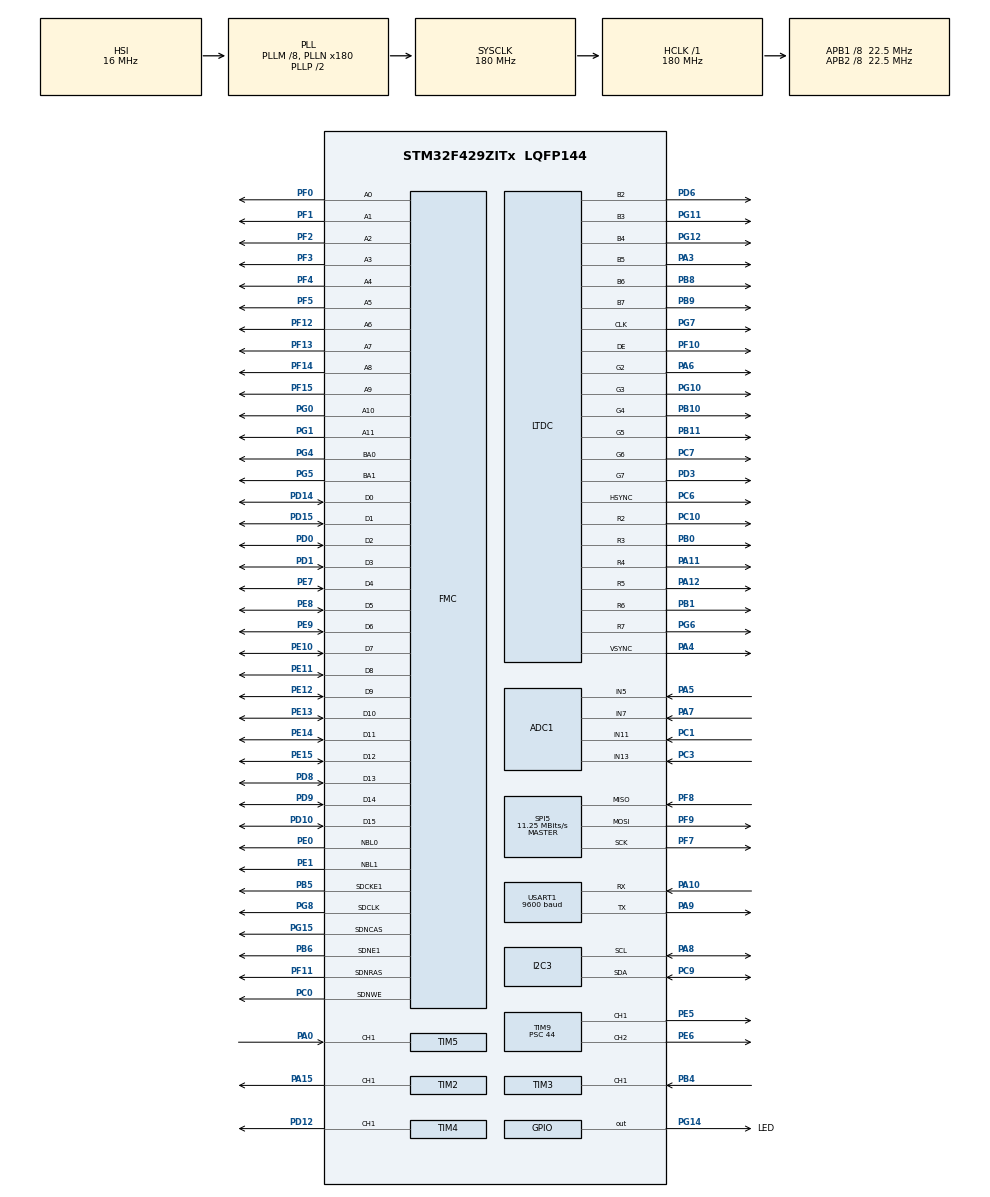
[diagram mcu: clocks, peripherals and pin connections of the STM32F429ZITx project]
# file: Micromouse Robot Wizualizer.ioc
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ADC1.Channel-1\#ChannelRegularConversion=ADC_CHANNEL_11
ADC1.NbrOfConversionFlag=1
ADC1.Rank-1\#ChannelRegularConversion=1
ADC1.SamplingTime-1\#ChannelRegularConversion=ADC_SAMPLETIME_3CYCLES
ADC1.master=1
DMA2D.ColorMode=DMA2D_OUTPUT_RGB565
LTDC.ActiveH=240
LTDC.ActiveW=320
Mcu.Family=STM32F4
Mcu.Name=STM32F429ZITx
Mcu.Package=LQFP144
NVIC.PriorityGroup=NVIC_PRIORITYGROUP_0
NVIC.USART1_IRQn=true\:0\:0\:false\:false\:true\:true\:true
PA0/WKUP.Signal=S_TIM5_CH1
PA10.Mode=Asynchronous
PA10.Signal=USART1_RX
PA11.Mode=RGB666
PA11.Signal=LTDC_R4
PA12.Mode=RGB666
PA12.Signal=LTDC_R5
PA15.Signal=S_TIM2_CH1_ETR
PA3.Mode=RGB666
PA3.Signal=LTDC_B5
PA4.Mode=RGB666
PA4.Signal=LTDC_VSYNC
PA5.Signal=ADCx_IN5
PA6.Mode=RGB666
PA6.Signal=LTDC_G2
PA7.Signal=ADCx_IN7
PA8.Mode=I2C
PA8.Signal=I2C3_SCL
PA9.Mode=Asynchronous
PA9.Signal=USART1_TX
PB0.Mode=RGB666
PB0.Signal=LTDC_R3
PB1.Mode=RGB666
PB1.Signal=LTDC_R6
PB10.Mode=RGB666
PB10.Signal=LTDC_G4
PB11.Mode=RGB666
PB11.Signal=LTDC_G5
PB4.GPIO_Speed=GPIO_SPEED_FREQ_HIGH
PB4.Signal=S_TIM3_CH1
PB5.Mode=SdramChipSelect2_1
PB5.Signal=FMC_SDCKE1
PB6.Mode=SdramChipSelect2_1
PB6.Signal=FMC_SDNE1
PB8.Mode=RGB666
PB8.Signal=LTDC_B6
PB9.Mode=RGB666
PB9.Signal=LTDC_B7
PC0.Signal=FMC_SDNWE
PC1.Signal=ADCx_IN11
PC10.Mode=RGB666
PC10.Signal=LTDC_R2
PC3.Signal=ADCx_IN13
PC6.Mode=RGB666
PC6.Signal=LTDC_HSYNC
PC7.Mode=RGB666
PC7.Signal=LTDC_G6
PC9.Mode=I2C
PC9.Signal=I2C3_SDA
PD0.Signal=FMC_D2_DA2
PD1.Signal=FMC_D3_DA3
PD10.Signal=FMC_D15_DA15
PD12.GPIO_PuPd=GPIO_NOPULL
PD12.Signal=S_TIM4_CH1
PD14.Signal=FMC_D0_DA0
PD15.Signal=FMC_D1_DA1
PD3.Mode=RGB666
PD3.Signal=LTDC_G7
PD6.Mode=RGB666
PD6.Signal=LTDC_B2
PD8.Signal=FMC_D13_DA13
PD9.Signal=FMC_D14_DA14
PE0.Signal=FMC_NBL0
PE1.Signal=FMC_NBL1
PE10.Signal=FMC_D7_DA7
PE11.Signal=FMC_D8_DA8
PE12.Signal=FMC_D9_DA9
PE13.Signal=FMC_D10_DA10
PE14.Signal=FMC_D11_DA11
PE15.Signal=FMC_D12_DA12
PE5.Signal=S_TIM9_CH1
PE6.Signal=S_TIM9_CH2
PE7.Signal=FMC_D4_DA4
PE8.Signal=FMC_D5_DA5
PE9.Signal=FMC_D6_DA6
PF0.Signal=FMC_A0
PF1.Signal=FMC_A1
PF10.Mode=RGB666
PF10.Signal=LTDC_DE
PF11.Signal=FMC_SDNRAS
PF12.Signal=FMC_A6
PF13.Signal=FMC_A7
PF14.Signal=FMC_A8
PF15.Signal=FMC_A9
PF2.Signal=FMC_A2
PF3.Signal=FMC_A3
PF4.Signal=FMC_A4
PF5.Signal=FMC_A5
PF7.Mode=Full_Duplex_Master
PF7.Signal=SPI5_SCK
PF8.Mode=Full_Duplex_Master
PF8.Signal=SPI5_MISO
PF9.Mode=Full_Duplex_Master
PF9.Signal=SPI5_MOSI
PG0.Signal=FMC_A10
PG1.Signal=FMC_A11
PG10.Mode=RGB666
PG10.Signal=LTDC_G3
PG11.Mode=RGB666
PG11.Signal=LTDC_B3
PG12.Mode=RGB666
PG12.Signal=LTDC_B4
PG14.GPIO_Label=LED
PG14.Signal=GPIO_Output
PG15.Signal=FMC_SDNCAS
PG4.Signal=FMC_A14_BA0
PG5.Signal=FMC_A15_BA1
PG6.Mode=RGB666
PG6.Signal=LTDC_R7
PG7.Mode=RGB666
PG7.Signal=LTDC_CLK
PG8.Signal=FMC_SDCLK
ProjectManager.HeapSize=0x200
ProjectManager.StackSize=0x400
ProjectManager.TargetToolchain=STM32CubeIDE
RCC.48MHZClocksFreq_Value=51428571.428571425
RCC.AHBFreq_Value=180000000
RCC.APB1CLKDivider=RCC_HCLK_DIV8
RCC.APB1Freq_Value=22500000
RCC.APB1TimFreq_Value=45000000
RCC.APB2CLKDivider=RCC_HCLK_DIV8
RCC.APB2Freq_Value=22500000
RCC.APB2TimFreq_Value=45000000
RCC.CortexFreq_Value=180000000
RCC.HCLKFreq_Value=180000000
RCC.HSE_VALUE=8000000
RCC.HSI_VALUE=16000000
RCC.LSE_VALUE=32768
RCC.PLLM=8
RCC.PLLN=180
RCC.PLLQ=7
RCC.PLLSAIN=216
RCC.SYSCLKFreq_VALUE=180000000
RCC.SYSCLKSource=RCC_SYSCLKSOURCE_PLLCLK
RCC.VCOOutputFreq_Value=360000000
SH.ADCx_IN11.0=ADC1_IN11,IN11
SH.ADCx_IN13.0=ADC1_IN13,IN13
SH.ADCx_IN5.0=ADC1_IN5,IN5
SH.ADCx_IN7.0=ADC1_IN7,IN7
SH.FMC_A0.0=FMC_A0,12b-sda1
SH.FMC_A1.0=FMC_A1,12b-sda1
SH.FMC_A10.0=FMC_A10,12b-sda1
SH.FMC_A11.0=FMC_A11,12b-sda1
SH.FMC_A14_BA0.0=FMC_BA0,FourSdramBanks1
SH.FMC_A15_BA1.0=FMC_BA1,FourSdramBanks1
SH.FMC_A2.0=FMC_A2,12b-sda1
SH.FMC_A3.0=FMC_A3,12b-sda1
SH.FMC_A4.0=FMC_A4,12b-sda1
SH.FMC_A5.0=FMC_A5,12b-sda1
SH.FMC_A6.0=FMC_A6,12b-sda1
SH.FMC_A7.0=FMC_A7,12b-sda1
SH.FMC_A8.0=FMC_A8,12b-sda1
SH.FMC_A9.0=FMC_A9,12b-sda1
SH.FMC_D0_DA0.0=FMC_D0,sd-16b-d1
SH.FMC_D10_DA10.0=FMC_D10,sd-16b-d1
SH.FMC_D11_DA11.0=FMC_D11,sd-16b-d1
SH.FMC_D12_DA12.0=FMC_D12,sd-16b-d1
SH.FMC_D13_DA13.0=FMC_D13,sd-16b-d1
SH.FMC_D14_DA14.0=FMC_D14,sd-16b-d1
SH.FMC_D15_DA15.0=FMC_D15,sd-16b-d1
SH.FMC_D1_DA1.0=FMC_D1,sd-16b-d1
SH.FMC_D2_DA2.0=FMC_D2,sd-16b-d1
SH.FMC_D3_DA3.0=FMC_D3,sd-16b-d1
SH.FMC_D4_DA4.0=FMC_D4,sd-16b-d1
SH.FMC_D5_DA5.0=FMC_D5,sd-16b-d1
SH.FMC_D6_DA6.0=FMC_D6,sd-16b-d1
SH.FMC_D7_DA7.0=FMC_D7,sd-16b-d1
SH.FMC_D8_DA8.0=FMC_D8,sd-16b-d1
SH.FMC_D9_DA9.0=FMC_D9,sd-16b-d1
SH.FMC_NBL0.0=FMC_NBL0,Sd2ByteEnable1
SH.FMC_NBL1.0=FMC_NBL1,Sd2ByteEnable1
SH.FMC_SDCLK.0=FMC_SDCLK,12b-sda1
SH.FMC_SDNCAS.0=FMC_SDNCAS,12b-sda1
SH.FMC_SDNRAS.0=FMC_SDNRAS,12b-sda1
SH.FMC_SDNWE.0=FMC_SDNWE,12b-sda1
SH.S_TIM2_CH1_ETR.0=TIM2_CH1,PWM Generation1 CH1
SH.S_TIM3_CH1.0=TIM3_CH1,TriggerSource_TI1FP1
SH.S_TIM4_CH1.0=TIM4_CH1,PWM Generation1 CH1
SH.S_TIM5_CH1.0=TIM5_CH1,TriggerSource_TI1FP1
SH.S_TIM9_CH1.0=TIM9_CH1,PWM Generation1 CH1
SH.S_TIM9_CH2.0=TIM9_CH2,PWM Generation2 CH2
SPI5.CalculateBaudRate=11.25 MBits/s
SPI5.Direction=SPI_DIRECTION_2LINES
SPI5.Mode=SPI_MODE_MASTER
SPI5.VirtualType=VM_MASTER
TIM2.Channel-PWM\ Generation1\ CH1=TIM_CHANNEL_1
TIM2.Period=999
TIM2.Prescaler=44
TIM2.Pulse-PWM\ Generation1\ CH1=0
TIM3.Period=0xFFFF
TIM4.Channel-PWM\ Generation1\ CH1=TIM_CHANNEL_1
TIM4.Period=999
TIM4.Prescaler=44
TIM4.Pulse-PWM\ Generation1\ CH1=0
TIM5.Period=0xFFFFFFFF
TIM5.Slave_TriggerFilter=0
TIM9.Channel-PWM\ Generation1\ CH1=TIM_CHANNEL_1
TIM9.Channel-PWM\ Generation2\ CH2=TIM_CHANNEL_2
TIM9.Period=999
TIM9.Prescaler=44
TIM9.Pulse-PWM\ Generation1\ CH1=0
TIM9.Pulse-PWM\ Generation2\ CH2=0
USART1.BaudRate=9600
USART1.VirtualMode=VM_ASYNC
VP_DMA2D_VS_DMA2D.Mode=DMA2D_Activate
VP_TIM3_VS_ControllerModeClock.Mode=Clock Mode
VP_TIM5_VS_ControllerModeClock.Mode=Clock Mode
board=STM32F429I-DISC1

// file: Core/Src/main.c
/* USER CODE BEGIN Header */
/**
  ******************************************************************************
  * @file           : main.c
  * @brief          : Main program body
  ******************************************************************************
  * @attention
  *
  * <h2><center>&copy; Copyright (c) 2020 STMicroelectronics.
  * All rights reserved.</center></h2>
  *
  * This software component is licensed by ST under BSD 3-Clause license,
  * the "License"; You may not use this file except in compliance with the
  * License. You may obtain a copy of the License at:
  *                        opensource.org/licenses/BSD-3-Clause
  *
  ******************************************************************************
  */
/* USER CODE END Header */

#include "main.h"
#include "adc.h"
#include "dma2d.h"
#include "i2c.h"
#include "ltdc.h"
#include "spi.h"
#include "tim.h"
#include "usart.h"
#include "gpio.h"
#include "fmc.h"

/* USER CODE BEGIN Includes */
#include "stm32f429i_discovery_lcd.h"
#include "robot.h"
#include "funkcje_rysujace.h"
#include <stdlib.h>
/* USER CODE END Includes */

/* USER CODE BEGIN PV */
int przejechano = 0; 		// Zmienna pomocnicza zapobiegajaca cyklicznemu rysowaniu sie na wyswietlaczu
Robot robot; 	// Obiekt robota (pozycja x, pozycja y, orientacja)
uint8_t odebraneDane; 		// Dane odebrane od modulu Bluetooth
/* USER CODE END PV */

void SystemClock_Config(void);
/* USER CODE BEGIN PFP */

// Przerwanie dla odebrania danych z modulu BT
void HAL_UART_RxCpltCallback(UART_HandleTypeDef *huart) {
	switch(atoi(&odebraneDane)) {
	case 0:
		rysujDebug(0);
		robot.jedz = 0;
		__HAL_TIM_SET_COMPARE(&htim9, TIM_CHANNEL_1, 0);
		__HAL_TIM_SET_COMPARE(&htim4, TIM_CHANNEL_1, 0);
		__HAL_TIM_SET_COMPARE(&htim2, TIM_CHANNEL_1, 0);
		__HAL_TIM_SET_COMPARE(&htim9, TIM_CHANNEL_2, 0);
	break;
	case 1:
		rysujDebug(1);
		robot.jedz = 1;
	break;
	case 2:
		rysujDebug(2);
	break;
	case 3:
		rysujDebug(3);
	break;
	}
	HAL_UART_Receive_IT(&huart1, &odebraneDane, 1);
}

/* USER CODE END PFP */

int main(void)
{
  /* USER CODE BEGIN 1 */
  robot = konstruktorRobota(0, 0, Wschod);
  /* USER CODE END 1 */

  /* MCU Configuration--------------------------------------------------------*/

  /* Reset of all peripherals, Initializes the Flash interface and the Systick. */
  HAL_Init();

  /* Configure the system clock */
  SystemClock_Config();

  /* Initialize all configured peripherals */
  MX_GPIO_Init();
  MX_TIM4_Init();
  MX_ADC1_Init();
  MX_DMA2D_Init();
  MX_FMC_Init();
  MX_I2C3_Init();
  MX_LTDC_Init();
  MX_SPI5_Init();
  MX_TIM2_Init();
  MX_TIM9_Init();
  MX_USART1_UART_Init();
  MX_TIM5_Init();
  MX_TIM3_Init();
  /* USER CODE BEGIN 2 */
  HAL_UART_Receive_IT(&huart1, &odebraneDane, 1); // odebieranie danych z BT o wielkosci 1

  // Inicjalizacja LCD
  BSP_LCD_Init();
  BSP_LCD_LayerDefaultInit(LCD_BACKGROUND_LAYER, LCD_FRAME_BUFFER);
  BSP_LCD_LayerDefaultInit(LCD_FOREGROUND_LAYER, LCD_FRAME_BUFFER);
  BSP_LCD_SelectLayer(LCD_FOREGROUND_LAYER);
  BSP_LCD_DisplayOn();
  BSP_LCD_Clear(LCD_COLOR_WHITE);

  // Inicjalizacja PWM
  __HAL_TIM_SET_COMPARE(&htim4, TIM_CHANNEL_1, 0);
  HAL_TIM_PWM_Start(&htim4, TIM_CHANNEL_1);

  __HAL_TIM_SET_COMPARE(&htim2, TIM_CHANNEL_1, 0);
    HAL_TIM_PWM_Start(&htim2, TIM_CHANNEL_1);

  __HAL_TIM_SET_COMPARE(&htim9, TIM_CHANNEL_1, 0);
  HAL_TIM_PWM_Start(&htim9, TIM_CHANNEL_1);

  __HAL_TIM_SET_COMPARE(&htim9, TIM_CHANNEL_2, 0);
  HAL_TIM_PWM_Start(&htim9, TIM_CHANNEL_2);

  // Inicjalizacja ADC
  HAL_ADC_Start(&hadc1);

  // Inicjalizacja licznika enkodera
  HAL_TIM_Base_Start(&htim5);	// Enkoder R (PA0)
  HAL_TIM_Base_Start(&htim3);	// Enkoder L (P14)

  inicjalizujRysowanie();
  /* USER CODE END 2 */

  /* Infinite loop */
  /* USER CODE BEGIN WHILE */
  while (1)
  {
	skanujObszar(&robot);

	if(!przejechano && robot.jedz != 0) {
		przeszukajLabirynt(&robot);
		znajdzNajkrotszaSciezkeStart(&robot);

		przejechano = 1;
	}

	if(robot.jedz == 0) {
		__HAL_TIM_SET_COMPARE(&htim9, TIM_CHANNEL_1, 0);
		__HAL_TIM_SET_COMPARE(&htim4, TIM_CHANNEL_1, 0);
		__HAL_TIM_SET_COMPARE(&htim2, TIM_CHANNEL_1, 0);
		__HAL_TIM_SET_COMPARE(&htim9, TIM_CHANNEL_2, 0);
	}
	else {
		przejedzLabirynt(&robot);
	}

    /* USER CODE END WHILE */

  }
}

void SystemClock_Config(void)
{
  RCC_OscInitTypeDef RCC_OscInitStruct = {0};
  RCC_ClkInitTypeDef RCC_ClkInitStruct = {0};
  RCC_PeriphCLKInitTypeDef PeriphClkInitStruct = {0};

  /** Configure the main internal regulator output voltage
  */
  __HAL_RCC_PWR_CLK_ENABLE();
  __HAL_PWR_VOLTAGESCALING_CONFIG(PWR_REGULATOR_VOLTAGE_SCALE1);
  /** Initializes the CPU, AHB and APB busses clocks
  */
  RCC_OscInitStruct.OscillatorType = RCC_OSCILLATORTYPE_HSI;
  RCC_OscInitStruct.HSIState = RCC_HSI_ON;
  RCC_OscInitStruct.HSICalibrationValue = RCC_HSICALIBRATION_DEFAULT;
  RCC_OscInitStruct.PLL.PLLState = RCC_PLL_ON;
  RCC_OscInitStruct.PLL.PLLSource = RCC_PLLSOURCE_HSI;
  RCC_OscInitStruct.PLL.PLLM = 8;
  RCC_OscInitStruct.PLL.PLLN = 180;
  RCC_OscInitStruct.PLL.PLLP = RCC_PLLP_DIV2;
  RCC_OscInitStruct.PLL.PLLQ = 7;
  if (HAL_RCC_OscConfig(&RCC_OscInitStruct) != HAL_OK)
  {
    Error_Handler();
  }
  /** Activate the Over-Drive mode
  */
  if (HAL_PWREx_EnableOverDrive() != HAL_OK)
  {
    Error_Handler();
  }
  /** Initializes the CPU, AHB and APB busses clocks
  */
  RCC_ClkInitStruct.ClockType = RCC_CLOCKTYPE_HCLK|RCC_CLOCKTYPE_SYSCLK
                              |RCC_CLOCKTYPE_PCLK1|RCC_CLOCKTYPE_PCLK2;
  RCC_ClkInitStruct.SYSCLKSource = RCC_SYSCLKSOURCE_PLLCLK;
  RCC_ClkInitStruct.AHBCLKDivider = RCC_SYSCLK_DIV1;
  RCC_ClkInitStruct.APB1CLKDivider = RCC_HCLK_DIV8;
  RCC_ClkInitStruct.APB2CLKDivider = RCC_HCLK_DIV8;

  if (HAL_RCC_ClockConfig(&RCC_ClkInitStruct, FLASH_LATENCY_5) != HAL_OK)
  {
    Error_Handler();
  }
  PeriphClkInitStruct.PeriphClockSelection = RCC_PERIPHCLK_LTDC;
  PeriphClkInitStruct.PLLSAI.PLLSAIN = 216;
  PeriphClkInitStruct.PLLSAI.PLLSAIR = 2;
  PeriphClkInitStruct.PLLSAIDivR = RCC_PLLSAIDIVR_2;
  if (HAL_RCCEx_PeriphCLKConfig(&PeriphClkInitStruct) != HAL_OK)
  {
    Error_Handler();
  }
}

void Error_Handler(void)
{
}

/************************ (C) COPYRIGHT STMicroelectronics *****END OF FILE****/
